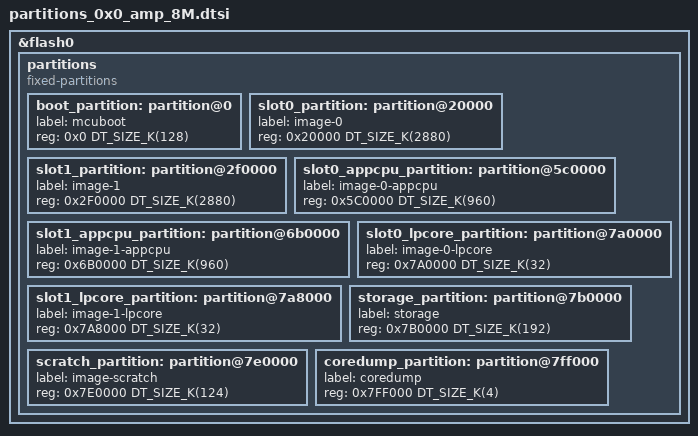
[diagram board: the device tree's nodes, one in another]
/*
 * Copyright (c) 2024-2025 Espressif Systems (Shanghai) Co., Ltd.
 *
 * SPDX-License-Identifier: Apache-2.0
 */

&flash0 {
	partitions {
		compatible = "fixed-partitions";
		#address-cells = <1>;
		#size-cells = <1>;

		boot_partition: partition@0 {
			label = "mcuboot";
			reg = <0x0 DT_SIZE_K(128)>;
		};

		slot0_partition: partition@20000 {
			label = "image-0";
			reg = <0x20000 DT_SIZE_K(2880)>;
		};

		slot1_partition: partition@2f0000 {
			label = "image-1";
			reg = <0x2F0000 DT_SIZE_K(2880)>;
		};

		slot0_appcpu_partition: partition@5c0000 {
			label = "image-0-appcpu";
			reg = <0x5C0000 DT_SIZE_K(960)>;
		};

		slot1_appcpu_partition: partition@6b0000 {
			label = "image-1-appcpu";
			reg = <0x6B0000 DT_SIZE_K(960)>;
		};

		slot0_lpcore_partition: partition@7a0000 {
			label = "image-0-lpcore";
			reg = <0x7A0000 DT_SIZE_K(32)>;
		};

		slot1_lpcore_partition: partition@7a8000 {
			label = "image-1-lpcore";
			reg = <0x7A8000 DT_SIZE_K(32)>;
		};

		storage_partition: partition@7b0000 {
			label = "storage";
			reg = <0x7B0000 DT_SIZE_K(192)>;
		};

		scratch_partition: partition@7e0000 {
			label = "image-scratch";
			reg = <0x7E0000 DT_SIZE_K(124)>;
		};

		coredump_partition: partition@7ff000 {
			label = "coredump";
			reg = <0x7FF000 DT_SIZE_K(4)>;
		};
	};
};

/* Remaining flash size is 0kB
 * Last used address is 0x7FFFFF
 */
